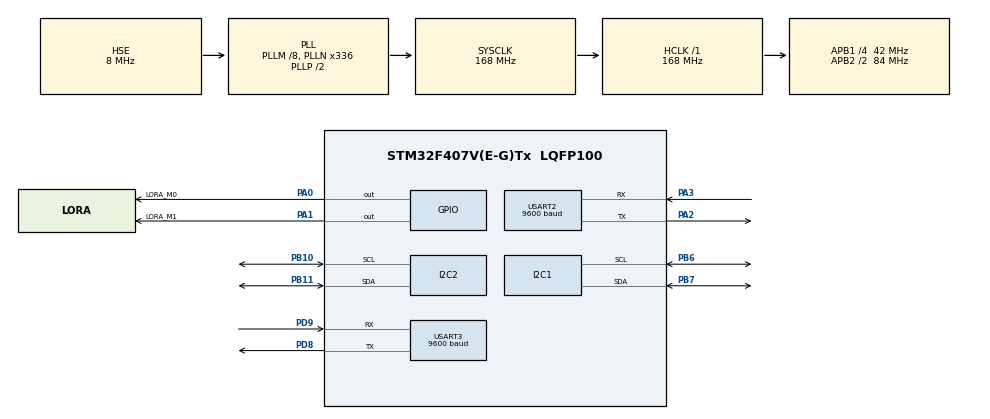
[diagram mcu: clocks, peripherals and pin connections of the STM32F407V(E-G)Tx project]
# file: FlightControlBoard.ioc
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Dma.Request0=USART3_RX
Dma.USART3_RX.0.Direction=DMA_PERIPH_TO_MEMORY
Dma.USART3_RX.0.FIFOMode=DMA_FIFOMODE_DISABLE
Dma.USART3_RX.0.Instance=DMA1_Stream1
Dma.USART3_RX.0.MemDataAlignment=DMA_MDATAALIGN_BYTE
Dma.USART3_RX.0.MemInc=DMA_MINC_ENABLE
Dma.USART3_RX.0.Mode=DMA_NORMAL
Dma.USART3_RX.0.PeriphDataAlignment=DMA_PDATAALIGN_BYTE
Dma.USART3_RX.0.PeriphInc=DMA_PINC_DISABLE
Dma.USART3_RX.0.Priority=DMA_PRIORITY_LOW
FREERTOS.HEAP_NUMBER=1
FREERTOS.Mutexes01=telemetryMutex,Dynamic,NULL
FREERTOS.Tasks01=gpsTask,0,256,StartGpsTask,Default,NULL,Dynamic,NULL,NULL;bmeTask,0,256,StartBmeTask,Default,NULL,Dynamic,NULL,NULL;mpuTask,0,256,StartMpuTask,Default,NULL,Dynamic,NULL,NULL;loraTask,0,384,StartLoraTask,Default,NULL,Dynamic,NULL,NULL;iwdgTask,1,128,StartWatchdogTask,Default,NULL,Dynamic,NULL,NULL;testTask,0,256,StartTestTask,Default,NULL,Dynamic,NULL,NULL
FREERTOS.configUSE_NEWLIB_REENTRANT=1
IWDG.Prescaler=IWDG_PRESCALER_64
Mcu.Family=STM32F4
Mcu.Name=STM32F407V(E-G)Tx
Mcu.Package=LQFP100
NVIC.DMA1_Stream1_IRQn=true\:5\:0\:false\:false\:true\:true\:false\:true\:true
NVIC.PriorityGroup=NVIC_PRIORITYGROUP_4
NVIC.TIM6_DAC_IRQn=true\:0\:0\:false\:false\:true\:false\:false\:true\:true
NVIC.TimeBase=TIM6_DAC_IRQn
NVIC.TimeBaseIP=TIM6
NVIC.USART3_IRQn=true\:5\:0\:false\:false\:true\:true\:true\:true\:true
PA0-WKUP.GPIO_Label=LORA_M0
PA0-WKUP.Signal=GPIO_Output
PA1.GPIO_Label=LORA_M1
PA1.Signal=GPIO_Output
PA13.Mode=Serial_Wire
PA13.Signal=SYS_JTMS-SWDIO
PA14.Mode=Serial_Wire
PA14.Signal=SYS_JTCK-SWCLK
PA2.Mode=Asynchronous
PA2.Signal=USART2_TX
PA3.Mode=Asynchronous
PA3.Signal=USART2_RX
PB10.Mode=I2C
PB10.Signal=I2C2_SCL
PB11.Mode=I2C
PB11.Signal=I2C2_SDA
PB6.Mode=I2C
PB6.Signal=I2C1_SCL
PB7.Mode=I2C
PB7.Signal=I2C1_SDA
PD8.Mode=Asynchronous
PD8.Signal=USART3_TX
PD9.Mode=Asynchronous
PD9.Signal=USART3_RX
PH0-OSC_IN.Mode=HSE-External-Oscillator
PH0-OSC_IN.Signal=RCC_OSC_IN
PH1-OSC_OUT.Mode=HSE-External-Oscillator
PH1-OSC_OUT.Signal=RCC_OSC_OUT
ProjectManager.HeapSize=0x200
ProjectManager.StackSize=0x400
ProjectManager.TargetToolchain=STM32CubeIDE
RCC.48MHZClocksFreq_Value=48000000
RCC.AHBFreq_Value=168000000
RCC.APB1CLKDivider=RCC_HCLK_DIV4
RCC.APB1Freq_Value=42000000
RCC.APB1TimFreq_Value=84000000
RCC.APB2CLKDivider=RCC_HCLK_DIV2
RCC.APB2Freq_Value=84000000
RCC.APB2TimFreq_Value=168000000
RCC.CortexFreq_Value=168000000
RCC.HCLKFreq_Value=168000000
RCC.HSE_VALUE=8000000
RCC.HSI_VALUE=16000000
RCC.LSE_VALUE=32768
RCC.PLLM=8
RCC.PLLN=336
RCC.PLLQ=7
RCC.PLLSourceVirtual=RCC_PLLSOURCE_HSE
RCC.SYSCLKFreq_VALUE=168000000
RCC.SYSCLKSource=RCC_SYSCLKSOURCE_PLLCLK
RCC.VCOOutputFreq_Value=336000000
USART2.BaudRate=9600
USART2.VirtualMode=VM_ASYNC
USART3.BaudRate=9600
USART3.VirtualMode=VM_ASYNC
VP_FREERTOS_VS_CMSIS_V1.Mode=CMSIS_V1
VP_IWDG_VS_IWDG.Mode=IWDG_Activate
VP_SYS_VS_tim6.Mode=TIM6
board=STM32F407G-DISC1

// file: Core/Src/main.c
/* USER CODE BEGIN Header */
/**
  ******************************************************************************
  * @file           : main.c
  * @brief          : Main program body
  ******************************************************************************
  * @attention
  *
  * Copyright (c) 2026 STMicroelectronics.
  * All rights reserved.
  *
  * This software is licensed under terms that can be found in the LICENSE file
  * in the root directory of this software component.
  * If no LICENSE file comes with this software, it is provided AS-IS.
  *
  ******************************************************************************
  */
/* USER CODE END Header */
#include "main.h"
#include "cmsis_os.h"

/* USER CODE BEGIN Includes */
#include <stdio.h>
#include "test_runner.h"
#include "gps_driver.h"
#include "telemetry_data.h"
/* USER CODE END Includes */

I2C_HandleTypeDef hi2c1;
I2C_HandleTypeDef hi2c2;

IWDG_HandleTypeDef hiwdg;

UART_HandleTypeDef huart2;
UART_HandleTypeDef huart3;
DMA_HandleTypeDef hdma_usart3_rx;

osThreadId gpsTaskHandle;
osThreadId bmeTaskHandle;
osThreadId mpuTaskHandle;
osThreadId loraTaskHandle;
osThreadId iwdgTaskHandle;
osThreadId testTaskHandle;
osMutexId telemetryMutexHandle;

void SystemClock_Config(void);
static void MX_GPIO_Init(void);
static void MX_DMA_Init(void);
static void MX_USART3_UART_Init(void);
static void MX_USART2_UART_Init(void);
static void MX_I2C2_Init(void);
static void MX_I2C1_Init(void);
static void MX_IWDG_Init(void);
void StartGpsTask(void const * argument);
void StartBmeTask(void const * argument);
void StartMpuTask(void const * argument);
void StartLoraTask(void const * argument);
void StartWatchdogTask(void const * argument);
void StartTestTask(void const * argument);

/* USER CODE BEGIN 0 */
void HAL_UARTEx_RxEventCallback(UART_HandleTypeDef *huart, uint16_t Size)
{
    Gps_RxCallback(huart, Size);
}

void HAL_UART_ErrorCallback(UART_HandleTypeDef *huart)
{
    if (huart == &huart3)
    {
        Gps_RxErrorCallback(huart);
    }
}
/* USER CODE END 0 */

int main(void)
{

  /* MCU Configuration--------------------------------------------------------*/

  /* Reset of all peripherals, Initializes the Flash interface and the Systick. */
  HAL_Init();

  /* Configure the system clock */
  SystemClock_Config();

  /* Initialize all configured peripherals */
  MX_GPIO_Init();
  MX_DMA_Init();
  MX_USART3_UART_Init();
  MX_USART2_UART_Init();
  MX_I2C2_Init();
  MX_I2C1_Init();
  MX_IWDG_Init();
  /* USER CODE BEGIN 2 */

//  buffer_who = WhoAmI(&buffer_who);

  /* USER CODE END 2 */

  /* Create the mutex(es) */
  /* definition and creation of telemetryMutex */
  osMutexDef(telemetryMutex);
  telemetryMutexHandle = osMutexCreate(osMutex(telemetryMutex));

  TelemetryData_Init();

  #if !TEST_ENABLE
  /* Create the thread(s) */
  /* definition and creation of gpsTask */
  osThreadDef(gpsTask, StartGpsTask, osPriorityNormal, 0, 256);
  gpsTaskHandle = osThreadCreate(osThread(gpsTask), NULL);

  /* definition and creation of bmeTask */
  osThreadDef(bmeTask, StartBmeTask, osPriorityNormal, 0, 256);
  bmeTaskHandle = osThreadCreate(osThread(bmeTask), NULL);

  /* definition and creation of mpuTask */
  osThreadDef(mpuTask, StartMpuTask, osPriorityNormal, 0, 256);
  mpuTaskHandle = osThreadCreate(osThread(mpuTask), NULL);

  /* definition and creation of loraTask */
  osThreadDef(loraTask, StartLoraTask, osPriorityNormal, 0, 384);
  loraTaskHandle = osThreadCreate(osThread(loraTask), NULL);

  /* definition and creation of iwdgTask */
  osThreadDef(iwdgTask, StartWatchdogTask, osPriorityAboveNormal, 0, 128);
  iwdgTaskHandle = osThreadCreate(osThread(iwdgTask), NULL);

  #else

  /* definition and creation of testTask */
  osThreadDef(testTask, StartTestTask, osPriorityNormal, 0, 256);
  testTaskHandle = osThreadCreate(osThread(testTask), NULL);

  #endif

  /* Start scheduler */
  osKernelStart();

  /* We should never get here as control is now taken by the scheduler */
  /* Infinite loop */
  while (1)
  {

  }
}

void SystemClock_Config(void)
{
  RCC_OscInitTypeDef RCC_OscInitStruct = {0};
  RCC_ClkInitTypeDef RCC_ClkInitStruct = {0};

  /** Configure the main internal regulator output voltage
  */
  __HAL_RCC_PWR_CLK_ENABLE();
  __HAL_PWR_VOLTAGESCALING_CONFIG(PWR_REGULATOR_VOLTAGE_SCALE1);

  /** Initializes the RCC Oscillators according to the specified parameters
  * in the RCC_OscInitTypeDef structure.
  */
  RCC_OscInitStruct.OscillatorType = RCC_OSCILLATORTYPE_LSI|RCC_OSCILLATORTYPE_HSE;
  RCC_OscInitStruct.HSEState = RCC_HSE_ON;
  RCC_OscInitStruct.LSIState = RCC_LSI_ON;
  RCC_OscInitStruct.PLL.PLLState = RCC_PLL_ON;
  RCC_OscInitStruct.PLL.PLLSource = RCC_PLLSOURCE_HSE;
  RCC_OscInitStruct.PLL.PLLM = 8;
  RCC_OscInitStruct.PLL.PLLN = 336;
  RCC_OscInitStruct.PLL.PLLP = RCC_PLLP_DIV2;
  RCC_OscInitStruct.PLL.PLLQ = 7;
  if (HAL_RCC_OscConfig(&RCC_OscInitStruct) != HAL_OK)
  {
    Error_Handler();
  }

  /** Initializes the CPU, AHB and APB buses clocks
  */
  RCC_ClkInitStruct.ClockType = RCC_CLOCKTYPE_HCLK|RCC_CLOCKTYPE_SYSCLK
                              |RCC_CLOCKTYPE_PCLK1|RCC_CLOCKTYPE_PCLK2;
  RCC_ClkInitStruct.SYSCLKSource = RCC_SYSCLKSOURCE_PLLCLK;
  RCC_ClkInitStruct.AHBCLKDivider = RCC_SYSCLK_DIV1;
  RCC_ClkInitStruct.APB1CLKDivider = RCC_HCLK_DIV4;
  RCC_ClkInitStruct.APB2CLKDivider = RCC_HCLK_DIV2;

  if (HAL_RCC_ClockConfig(&RCC_ClkInitStruct, FLASH_LATENCY_5) != HAL_OK)
  {
    Error_Handler();
  }
}

static void MX_I2C1_Init(void)
{

  hi2c1.Instance = I2C1;
  hi2c1.Init.ClockSpeed = 100000;
  hi2c1.Init.DutyCycle = I2C_DUTYCYCLE_2;
  hi2c1.Init.OwnAddress1 = 0;
  hi2c1.Init.AddressingMode = I2C_ADDRESSINGMODE_7BIT;
  hi2c1.Init.DualAddressMode = I2C_DUALADDRESS_DISABLE;
  hi2c1.Init.OwnAddress2 = 0;
  hi2c1.Init.GeneralCallMode = I2C_GENERALCALL_DISABLE;
  hi2c1.Init.NoStretchMode = I2C_NOSTRETCH_DISABLE;
  if (HAL_I2C_Init(&hi2c1) != HAL_OK)
  {
    Error_Handler();
  }

}

static void MX_I2C2_Init(void)
{

  hi2c2.Instance = I2C2;
  hi2c2.Init.ClockSpeed = 100000;
  hi2c2.Init.DutyCycle = I2C_DUTYCYCLE_2;
  hi2c2.Init.OwnAddress1 = 0;
  hi2c2.Init.AddressingMode = I2C_ADDRESSINGMODE_7BIT;
  hi2c2.Init.DualAddressMode = I2C_DUALADDRESS_DISABLE;
  hi2c2.Init.OwnAddress2 = 0;
  hi2c2.Init.GeneralCallMode = I2C_GENERALCALL_DISABLE;
  hi2c2.Init.NoStretchMode = I2C_NOSTRETCH_DISABLE;
  if (HAL_I2C_Init(&hi2c2) != HAL_OK)
  {
    Error_Handler();
  }

}

static void MX_IWDG_Init(void)
{

  hiwdg.Instance = IWDG;
  hiwdg.Init.Prescaler = IWDG_PRESCALER_64;
  hiwdg.Init.Reload = 4095;
  if (HAL_IWDG_Init(&hiwdg) != HAL_OK)
  {
    Error_Handler();
  }

}

static void MX_USART2_UART_Init(void)
{

  huart2.Instance = USART2;
  huart2.Init.BaudRate = 9600;
  huart2.Init.WordLength = UART_WORDLENGTH_8B;
  huart2.Init.StopBits = UART_STOPBITS_1;
  huart2.Init.Parity = UART_PARITY_NONE;
  huart2.Init.Mode = UART_MODE_TX_RX;
  huart2.Init.HwFlowCtl = UART_HWCONTROL_NONE;
  huart2.Init.OverSampling = UART_OVERSAMPLING_16;
  if (HAL_UART_Init(&huart2) != HAL_OK)
  {
    Error_Handler();
  }

}

static void MX_USART3_UART_Init(void)
{

  huart3.Instance = USART3;
  huart3.Init.BaudRate = 9600;
  huart3.Init.WordLength = UART_WORDLENGTH_8B;
  huart3.Init.StopBits = UART_STOPBITS_1;
  huart3.Init.Parity = UART_PARITY_NONE;
  huart3.Init.Mode = UART_MODE_TX_RX;
  huart3.Init.HwFlowCtl = UART_HWCONTROL_NONE;
  huart3.Init.OverSampling = UART_OVERSAMPLING_16;
  if (HAL_UART_Init(&huart3) != HAL_OK)
  {
    Error_Handler();
  }

}

static void MX_DMA_Init(void)
{

  /* DMA controller clock enable */
  __HAL_RCC_DMA1_CLK_ENABLE();

  /* DMA interrupt init */
  /* DMA1_Stream1_IRQn interrupt configuration */
  HAL_NVIC_SetPriority(DMA1_Stream1_IRQn, 5, 0);
  HAL_NVIC_EnableIRQ(DMA1_Stream1_IRQn);

}

static void MX_GPIO_Init(void)
{
  GPIO_InitTypeDef GPIO_InitStruct = {0};

  /* GPIO Ports Clock Enable */
  __HAL_RCC_GPIOH_CLK_ENABLE();
  __HAL_RCC_GPIOA_CLK_ENABLE();
  __HAL_RCC_GPIOB_CLK_ENABLE();
  __HAL_RCC_GPIOD_CLK_ENABLE();

  /*Configure GPIO pin Output Level */
  HAL_GPIO_WritePin(GPIOA, LORA_M0_Pin|LORA_M1_Pin, GPIO_PIN_RESET);

  /*Configure GPIO pins : LORA_M0_Pin LORA_M1_Pin */
  GPIO_InitStruct.Pin = LORA_M0_Pin|LORA_M1_Pin;
  GPIO_InitStruct.Mode = GPIO_MODE_OUTPUT_PP;
  GPIO_InitStruct.Pull = GPIO_NOPULL;
  GPIO_InitStruct.Speed = GPIO_SPEED_FREQ_LOW;
  HAL_GPIO_Init(GPIOA, &GPIO_InitStruct);

}

void HAL_TIM_PeriodElapsedCallback(TIM_HandleTypeDef *htim)
{
  if (htim->Instance == TIM6) {
    HAL_IncTick();
  }
}

void Error_Handler(void)
{
  __disable_irq();
  while (1)
  {
  }
}
